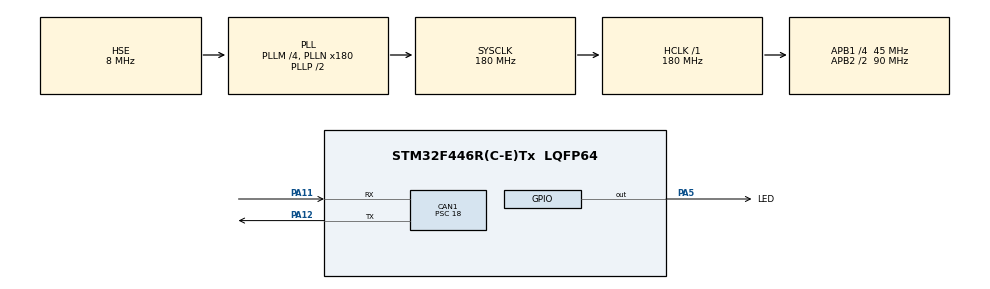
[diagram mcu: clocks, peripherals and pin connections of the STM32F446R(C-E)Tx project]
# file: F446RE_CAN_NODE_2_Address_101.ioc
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CAN1.BS1=CAN_BS1_2TQ
CAN1.BS2=CAN_BS2_2TQ
CAN1.CalculateBaudRate=500000
CAN1.CalculateTimeBit=2000
CAN1.CalculateTimeQuantum=400.0
CAN1.Prescaler=18
Mcu.Family=STM32F4
Mcu.Name=STM32F446R(C-E)Tx
Mcu.Package=LQFP64
NVIC.CAN1_RX1_IRQn=true\:0\:0\:false\:false\:true\:true\:true\:true
NVIC.PriorityGroup=NVIC_PRIORITYGROUP_0
PA11.Mode=CAN_Activate
PA11.Signal=CAN1_RX
PA12.Mode=CAN_Activate
PA12.Signal=CAN1_TX
PA5.GPIO_Label=LED
PA5.Signal=GPIO_Output
PH0-OSC_IN.Mode=HSE-External-Oscillator
PH0-OSC_IN.Signal=RCC_OSC_IN
PH1-OSC_OUT.Mode=HSE-External-Oscillator
PH1-OSC_OUT.Signal=RCC_OSC_OUT
ProjectManager.HeapSize=0x200
ProjectManager.StackSize=0x400
ProjectManager.TargetToolchain=STM32CubeIDE
RCC.48MHZClocksFreq_Value=84000000
RCC.AHBFreq_Value=180000000
RCC.APB1CLKDivider=RCC_HCLK_DIV4
RCC.APB1Freq_Value=45000000
RCC.APB1TimFreq_Value=90000000
RCC.APB2CLKDivider=RCC_HCLK_DIV2
RCC.APB2Freq_Value=90000000
RCC.APB2TimFreq_Value=180000000
RCC.CortexFreq_Value=180000000
RCC.FLatency-AdvancedSettings=FLASH_LATENCY_5
RCC.HCLKFreq_Value=180000000
RCC.HSE_VALUE=8000000
RCC.HSI_VALUE=16000000
RCC.PLLM=4
RCC.PLLN=180
RCC.PLLSourceVirtual=RCC_PLLSOURCE_HSE
RCC.SYSCLKFreq_VALUE=180000000
RCC.SYSCLKSource=RCC_SYSCLKSOURCE_PLLCLK
RCC.USBFreq_Value=180000000
RCC.VCOOutputFreq_Value=360000000
board=NUCLEO-F446RE

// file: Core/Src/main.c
/* USER CODE BEGIN Header */
/**
  ******************************************************************************
  * @file           : main.c
  * @brief          : Main program body
  ******************************************************************************
  * @attention
  *
  * Copyright (c) 2024 STMicroelectronics.
  * All rights reserved.
  *
  * This software is licensed under terms that can be found in the LICENSE file
  * in the root directory of this software component.
  * If no LICENSE file comes with this software, it is provided AS-IS.
  *
  ******************************************************************************
  */
/* USER CODE END Header */
#include "main.h"

CAN_HandleTypeDef hcan1;

/* USER CODE BEGIN PV */

CAN_TxHeaderTypeDef TxHeader;
CAN_RxHeaderTypeDef RxHeader;

uint8_t TxData[8];
uint8_t RxData[8];

uint32_t TxMailbox;

uint8_t datareceived = 0;

/* USER CODE END PV */

void SystemClock_Config(void);
static void MX_GPIO_Init(void);
static void MX_CAN1_Init(void);

/* USER CODE BEGIN 0 */

void HAL_CAN_RxFifo1MsgPendingCallback(CAN_HandleTypeDef *hcan)
{

	HAL_CAN_GetRxMessage(hcan, CAN_RX_FIFO1, &RxHeader, RxData);

	if(RxHeader.DLC == 2)
	{
		datareceived = 1;
	}
}
/* USER CODE END 0 */

int main(void)
{

  /* MCU Configuration--------------------------------------------------------*/

  /* Reset of all peripherals, Initializes the Flash interface and the Systick. */
  HAL_Init();

  /* Configure the system clock */
  SystemClock_Config();

  /* Initialize all configured peripherals */
  MX_GPIO_Init();
  MX_CAN1_Init();
  /* USER CODE BEGIN 2 */
  HAL_CAN_Start(&hcan1);

  HAL_CAN_ActivateNotification(&hcan1, CAN_IT_RX_FIFO1_MSG_PENDING);

  TxHeader.DLC = 2;
  TxHeader.StdId = 0x101;
  TxHeader.IDE = CAN_ID_STD;
  TxHeader.RTR = CAN_RTR_DATA;

  /* USER CODE END 2 */

  /* Infinite loop */
  /* USER CODE BEGIN WHILE */
  while (1)
  {
	  if(datareceived)
	  {
		  for(uint8_t i=0;i<RxData[0];i++)
		  {
			  HAL_GPIO_TogglePin(LED_GPIO_Port, LED_Pin);
			  HAL_Delay(RxData[1]);
		  }
		  datareceived = 0;

		  TxData[0] = 100;
		  TxData[1] = 100;
		  HAL_CAN_AddTxMessage(&hcan1, &TxHeader, TxData, &TxMailbox);
	  }
    /* USER CODE END WHILE */

  }
}

void SystemClock_Config(void)
{
  RCC_OscInitTypeDef RCC_OscInitStruct = {0};
  RCC_ClkInitTypeDef RCC_ClkInitStruct = {0};

  /** Configure the main internal regulator output voltage
  */
  __HAL_RCC_PWR_CLK_ENABLE();
  __HAL_PWR_VOLTAGESCALING_CONFIG(PWR_REGULATOR_VOLTAGE_SCALE1);

  /** Initializes the RCC Oscillators according to the specified parameters
  * in the RCC_OscInitTypeDef structure.
  */
  RCC_OscInitStruct.OscillatorType = RCC_OSCILLATORTYPE_HSE;
  RCC_OscInitStruct.HSEState = RCC_HSE_ON;
  RCC_OscInitStruct.PLL.PLLState = RCC_PLL_ON;
  RCC_OscInitStruct.PLL.PLLSource = RCC_PLLSOURCE_HSE;
  RCC_OscInitStruct.PLL.PLLM = 4;
  RCC_OscInitStruct.PLL.PLLN = 180;
  RCC_OscInitStruct.PLL.PLLP = RCC_PLLP_DIV2;
  RCC_OscInitStruct.PLL.PLLQ = 2;
  RCC_OscInitStruct.PLL.PLLR = 2;
  if (HAL_RCC_OscConfig(&RCC_OscInitStruct) != HAL_OK)
  {
    Error_Handler();
  }

  /** Activate the Over-Drive mode
  */
  if (HAL_PWREx_EnableOverDrive() != HAL_OK)
  {
    Error_Handler();
  }

  /** Initializes the CPU, AHB and APB buses clocks
  */
  RCC_ClkInitStruct.ClockType = RCC_CLOCKTYPE_HCLK|RCC_CLOCKTYPE_SYSCLK
                              |RCC_CLOCKTYPE_PCLK1|RCC_CLOCKTYPE_PCLK2;
  RCC_ClkInitStruct.SYSCLKSource = RCC_SYSCLKSOURCE_PLLCLK;
  RCC_ClkInitStruct.AHBCLKDivider = RCC_SYSCLK_DIV1;
  RCC_ClkInitStruct.APB1CLKDivider = RCC_HCLK_DIV4;
  RCC_ClkInitStruct.APB2CLKDivider = RCC_HCLK_DIV2;

  if (HAL_RCC_ClockConfig(&RCC_ClkInitStruct, FLASH_LATENCY_5) != HAL_OK)
  {
    Error_Handler();
  }
}

static void MX_CAN1_Init(void)
{

  hcan1.Instance = CAN1;
  hcan1.Init.Prescaler = 18;
  hcan1.Init.Mode = CAN_MODE_NORMAL;
  hcan1.Init.SyncJumpWidth = CAN_SJW_1TQ;
  hcan1.Init.TimeSeg1 = CAN_BS1_2TQ;
  hcan1.Init.TimeSeg2 = CAN_BS2_2TQ;
  hcan1.Init.TimeTriggeredMode = DISABLE;
  hcan1.Init.AutoBusOff = DISABLE;
  hcan1.Init.AutoWakeUp = DISABLE;
  hcan1.Init.AutoRetransmission = DISABLE;
  hcan1.Init.ReceiveFifoLocked = DISABLE;
  hcan1.Init.TransmitFifoPriority = DISABLE;
  if (HAL_CAN_Init(&hcan1) != HAL_OK)
  {
    Error_Handler();
  }
  /* USER CODE BEGIN CAN1_Init 2 */
  CAN_FilterTypeDef sfilterConfig = {0};

  sfilterConfig.FilterActivation = CAN_FILTER_ENABLE;
  sfilterConfig.FilterBank = 10;
  sfilterConfig.FilterFIFOAssignment = CAN_RX_FIFO1;
  sfilterConfig.FilterIdHigh = 0x100 << 5;
  sfilterConfig.FilterIdLow = 0x000;
  sfilterConfig.FilterMaskIdHigh = 0x100 << 5;
  sfilterConfig.FilterMaskIdLow = 0x000;
  sfilterConfig.FilterMode = CAN_FILTERMODE_IDMASK;
  sfilterConfig.FilterScale = CAN_FILTERSCALE_32BIT;
  sfilterConfig.SlaveStartFilterBank = 0;

  if(HAL_CAN_ConfigFilter(&hcan1, &sfilterConfig) != HAL_OK)
  {
	  Error_Handler();

  }
  /* USER CODE END CAN1_Init 2 */

}

static void MX_GPIO_Init(void)
{
  GPIO_InitTypeDef GPIO_InitStruct = {0};

  /* GPIO Ports Clock Enable */
  __HAL_RCC_GPIOH_CLK_ENABLE();
  __HAL_RCC_GPIOA_CLK_ENABLE();

  /*Configure GPIO pin Output Level */
  HAL_GPIO_WritePin(LED_GPIO_Port, LED_Pin, GPIO_PIN_RESET);

  /*Configure GPIO pin : LED_Pin */
  GPIO_InitStruct.Pin = LED_Pin;
  GPIO_InitStruct.Mode = GPIO_MODE_OUTPUT_PP;
  GPIO_InitStruct.Pull = GPIO_NOPULL;
  GPIO_InitStruct.Speed = GPIO_SPEED_FREQ_LOW;
  HAL_GPIO_Init(LED_GPIO_Port, &GPIO_InitStruct);

}

void Error_Handler(void)
{
  __disable_irq();
  while (1)
  {
  }
}
